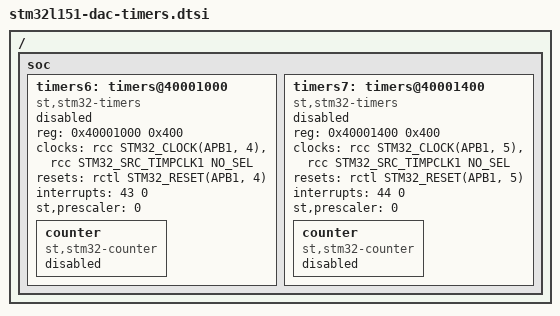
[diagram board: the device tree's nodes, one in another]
/* Define TIM6 and TIM7 since they are strangely absent from the built-in Zephyr device trees. */
/ {
	soc {
		timers6: timers@40001000 {
			compatible = "st,stm32-timers";
			reg = <0x40001000 0x400>;
			clocks = <&rcc STM32_CLOCK(APB1, 4)>,
					<&rcc STM32_SRC_TIMPCLK1 NO_SEL>;
			resets = <&rctl STM32_RESET(APB1, 4)>;
			interrupts = <43 0>;
			interrupt-names = "global";
			st,prescaler = <0>;
			status = "disabled";

			counter {
				compatible = "st,stm32-counter";
				status = "disabled";
			};
		};

		timers7: timers@40001400 {
			compatible = "st,stm32-timers";
			reg = <0x40001400 0x400>;
			clocks = <&rcc STM32_CLOCK(APB1, 5)>,
					<&rcc STM32_SRC_TIMPCLK1 NO_SEL>;
			resets = <&rctl STM32_RESET(APB1, 5)>;
			interrupts = <44 0>;
			interrupt-names = "global";
			st,prescaler = <0>;
			status = "disabled";

			counter {
				compatible = "st,stm32-counter";
				status = "disabled";
			};
		};
	};
};
